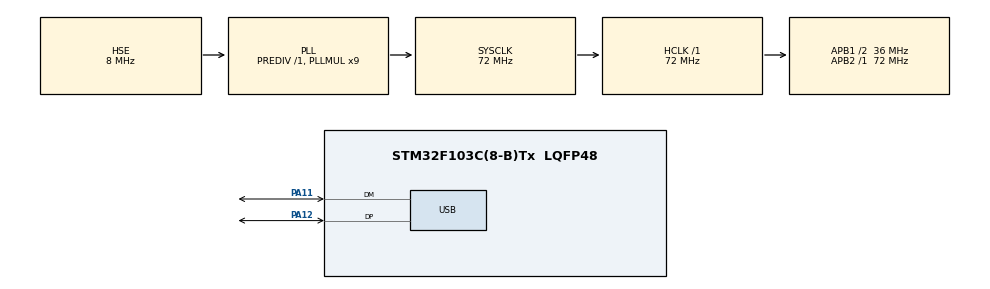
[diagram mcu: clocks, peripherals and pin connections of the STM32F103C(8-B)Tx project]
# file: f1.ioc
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FREERTOS.Tasks01=defaultTask,24,128,StartDefaultTask,Default,NULL,Dynamic,NULL,NULL
FREERTOS.configRECORD_STACK_HIGH_ADDRESS=1
FREERTOS.configTOTAL_HEAP_SIZE=10240
FREERTOS.configUSE_NEWLIB_REENTRANT=1
Mcu.Family=STM32F1
Mcu.Name=STM32F103C(8-B)Tx
Mcu.Package=LQFP48
NVIC.PriorityGroup=NVIC_PRIORITYGROUP_4
NVIC.TIM4_IRQn=true\:15\:0\:false\:false\:true\:false\:false\:true\:true
NVIC.TimeBase=TIM4_IRQn
NVIC.TimeBaseIP=TIM4
NVIC.USB_LP_CAN1_RX0_IRQn=true\:5\:0\:false\:false\:true\:true\:false\:true\:true
PA11.Mode=Device
PA11.Signal=USB_DM
PA12.Mode=Device
PA12.Signal=USB_DP
PA13.Mode=Trace_Asynchronous_SW
PA13.Signal=SYS_JTMS-SWDIO
PA14.Mode=Trace_Asynchronous_SW
PA14.Signal=SYS_JTCK-SWCLK
PB3.Mode=Trace_Asynchronous_SW
PB3.Signal=SYS_JTDO-TRACESWO
PD0-OSC_IN.Mode=HSE-External-Oscillator
PD0-OSC_IN.Signal=RCC_OSC_IN
PD1-OSC_OUT.Mode=HSE-External-Oscillator
PD1-OSC_OUT.Signal=RCC_OSC_OUT
ProjectManager.HeapSize=0x200
ProjectManager.StackSize=0x400
ProjectManager.TargetToolchain=CMake
RCC.AHBFreq_Value=72000000
RCC.APB1CLKDivider=RCC_HCLK_DIV2
RCC.APB1Freq_Value=36000000
RCC.APB1TimFreq_Value=72000000
RCC.APB2Freq_Value=72000000
RCC.APB2TimFreq_Value=72000000
RCC.HCLKFreq_Value=72000000
RCC.PLLMUL=RCC_PLL_MUL9
RCC.SYSCLKFreq_VALUE=72000000
RCC.SYSCLKSource=RCC_SYSCLKSOURCE_PLLCLK
RCC.USBFreq_Value=48000000
RCC.USBPrescaler=RCC_USBCLKSOURCE_PLL_DIV1_5
USB_DEVICE.CLASS_NAME_FS=CUSTOM_HID
USB_DEVICE.PID_CUSTOMHID_FS=0x82cd
USB_DEVICE.USBD_CUSTOMHID_OUTREPORT_BUF_SIZE=20
USB_DEVICE.USBD_CUSTOM_HID_REPORT_DESC_SIZE=34
USB_DEVICE.USBD_MAX_NUM_INTERFACES=1
USB_DEVICE.VID=0x10c4
USB_DEVICE.VirtualMode=CustomHid
USB_DEVICE.VirtualModeFS=Custom_Hid_FS
VP_FREERTOS_VS_CMSIS_V2.Mode=CMSIS_V2
VP_SYS_VS_tim4.Mode=TIM4
VP_USB_DEVICE_VS_USB_DEVICE_CUSTOM_HID_FS.Mode=CUSTOM_HID_FS
board=custom

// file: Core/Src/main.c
/* USER CODE BEGIN Header */
/**
  ******************************************************************************
  * @file           : main.c
  * @brief          : Main program body
  ******************************************************************************
  * @attention
  *
  * Copyright (c) 2024 STMicroelectronics.
  * All rights reserved.
  *
  * This software is licensed under terms that can be found in the LICENSE file
  * in the root directory of this software component.
  * If no LICENSE file comes with this software, it is provided AS-IS.
  *
  ******************************************************************************
  */
/* USER CODE END Header */
#include "main.h"
#include "cmsis_os.h"
#include "common.h"
#include "usb_device.h"

/* USER CODE BEGIN Includes */
#include <stdio.h>
#include <inttypes.h>
/* USER CODE END Includes */

/* USER CODE BEGIN PTD */
void swoInit(uint32_t portMask, uint32_t cpuCoreFreqHz, uint32_t baudrate);

/* USER CODE END PTD */

/* Definitions for defaultTask */
osThreadId_t defaultTaskHandle;
const osThreadAttr_t defaultTask_attributes = {
  .name = "defaultTask",
  .stack_size = 128 * 4,
  .priority = (osPriority_t) osPriorityNormal,
};

void SystemClock_Config(void);
static void MX_GPIO_Init(void);
void StartDefaultTask(void *argument);

/* USER CODE BEGIN PFP */
commdat com = {0};
osSemaphoreDef _wifisemdef;
/* USER CODE END PFP */

int main(void)
{

  /* MCU Configuration--------------------------------------------------------*/

  /* Reset of all peripherals, Initializes the Flash interface and the Systick. */
  HAL_Init();

  /* Configure the system clock */
  SystemClock_Config();

  /* Initialize all configured peripherals */
  MX_GPIO_Init();

  /* Init scheduler */
  osKernelInitialize();

  /* Create the thread(s) */
  /* creation of defaultTask */
  defaultTaskHandle[0] = osThreadNew(StartDefaultTask, NULL, &defaultTask_attributes);
  defaultTaskHandle[1] = osThreadNew(wifi_recv, NULL, &defaultTask_attributes);
  defaultTaskHandle[2] = osThreadNew(wifi_send, NULL, &defaultTask_attributes);

  defaultTaskHandle[3] = osThreadNew(cmd_line, NULL, &defaultTask_attributes);
  defaultTaskHandle[4] = osThreadNew(c22gs, NULL, &defaultTask_attributes);

  /* USER CODE BEGIN RTOS_EVENTS */
  /* add events, ... */
  com.wifisem = osSemaphoreCreate(_wifisemdef, 1);
  /* USER CODE END RTOS_EVENTS */

  /* Start scheduler */
  osKernelStart();

  /* We should never get here as control is now taken by the scheduler */

  /* Infinite loop */
  while (1)
  {

  }
}

void SystemClock_Config(void)
{
  RCC_OscInitTypeDef RCC_OscInitStruct = {0};
  RCC_ClkInitTypeDef RCC_ClkInitStruct = {0};
  RCC_PeriphCLKInitTypeDef PeriphClkInit = {0};

  /** Initializes the RCC Oscillators according to the specified parameters
  * in the RCC_OscInitTypeDef structure.
  */
  RCC_OscInitStruct.OscillatorType = RCC_OSCILLATORTYPE_HSE;
  RCC_OscInitStruct.HSEState = RCC_HSE_ON;
  RCC_OscInitStruct.HSEPredivValue = RCC_HSE_PREDIV_DIV1;
  RCC_OscInitStruct.HSIState = RCC_HSI_ON;
  RCC_OscInitStruct.PLL.PLLState = RCC_PLL_ON;
  RCC_OscInitStruct.PLL.PLLSource = RCC_PLLSOURCE_HSE;
  RCC_OscInitStruct.PLL.PLLMUL = RCC_PLL_MUL9;
  if (HAL_RCC_OscConfig(&RCC_OscInitStruct) != HAL_OK)
  {
    Error_Handler();
  }

  /** Initializes the CPU, AHB and APB buses clocks
  */
  RCC_ClkInitStruct.ClockType = RCC_CLOCKTYPE_HCLK|RCC_CLOCKTYPE_SYSCLK
                              |RCC_CLOCKTYPE_PCLK1|RCC_CLOCKTYPE_PCLK2;
  RCC_ClkInitStruct.SYSCLKSource = RCC_SYSCLKSOURCE_PLLCLK;
  RCC_ClkInitStruct.AHBCLKDivider = RCC_SYSCLK_DIV1;
  RCC_ClkInitStruct.APB1CLKDivider = RCC_HCLK_DIV2;
  RCC_ClkInitStruct.APB2CLKDivider = RCC_HCLK_DIV1;

  if (HAL_RCC_ClockConfig(&RCC_ClkInitStruct, FLASH_LATENCY_2) != HAL_OK)
  {
    Error_Handler();
  }
  PeriphClkInit.PeriphClockSelection = RCC_PERIPHCLK_USB;
  PeriphClkInit.UsbClockSelection = RCC_USBCLKSOURCE_PLL_DIV1_5;
  if (HAL_RCCEx_PeriphCLKConfig(&PeriphClkInit) != HAL_OK)
  {
    Error_Handler();
  }
}

static void MX_GPIO_Init(void)
{

  /* GPIO Ports Clock Enable */
  __HAL_RCC_GPIOD_CLK_ENABLE();
  __HAL_RCC_GPIOA_CLK_ENABLE();
  __HAL_RCC_GPIOB_CLK_ENABLE();

/* USER CODE BEGIN MX_GPIO_Init_2 */
  GPIO_InitTypeDef GPIO_InitStruct;
  /* GPIO Ports Clock Enable */
  __HAL_RCC_GPIOA_CLK_ENABLE();
  /*Configure GPIO pin Output Level */
  HAL_GPIO_WritePin(GPIOA, GPIO_PIN_12, GPIO_PIN_RESET);
  /*Configure GPIO pin : PA12 */
  GPIO_InitStruct.Pin = GPIO_PIN_12;
  GPIO_InitStruct.Mode = GPIO_MODE_OUTPUT_PP;
  GPIO_InitStruct.Pull = GPIO_PULLDOWN;
  GPIO_InitStruct.Speed = GPIO_SPEED_FREQ_LOW;
  HAL_GPIO_Init(GPIOA, &GPIO_InitStruct);

  HAL_GPIO_WritePin(GPIOA, GPIO_PIN_12,
  GPIO_PIN_RESET);
  HAL_Delay(65);
  HAL_GPIO_WritePin(GPIOA,GPIO_PIN_12,GPIO_PIN_SET);
  HAL_Delay(65);
/* USER CODE END MX_GPIO_Init_2 */
}

void StartDefaultTask(void *argument)
{
  /* init code for USB_DEVICE */
  MX_USB_DEVICE_Init();
  /* USER CODE BEGIN 5 */
  swoInit(1,72000000,875000);
  printf("swo init!!\n");
  UNUSED(argument);
  /* Infinite loop */
  for(;;)
  {

      // CDC_Transmit_FS((uint8_t*)testbuff, sdlen);
      osDelay(100);
  }
  /* USER CODE END 5 */
}

void HAL_TIM_PeriodElapsedCallback(TIM_HandleTypeDef *htim)
{
  if (htim->Instance == TIM4) {
    HAL_IncTick();
  }
}

void Error_Handler(void)
{
  __disable_irq();
  while (1)
  {
  }
}
